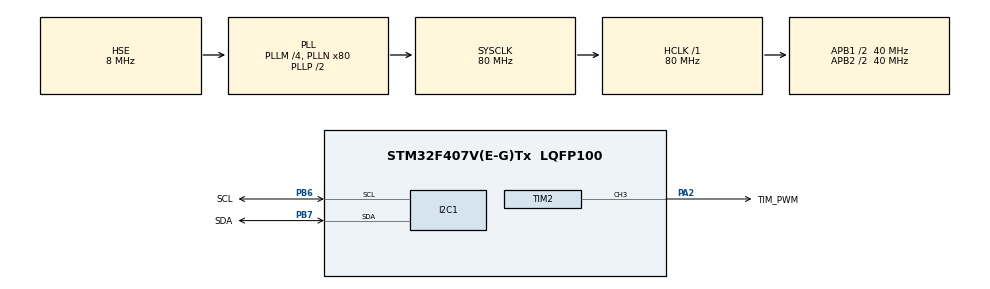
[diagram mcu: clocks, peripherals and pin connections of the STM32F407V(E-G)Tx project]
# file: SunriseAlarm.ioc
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I2C1.I2C_Mode=I2C_Fast
Mcu.Family=STM32F4
Mcu.Name=STM32F407V(E-G)Tx
Mcu.Package=LQFP100
NVIC.PriorityGroup=NVIC_PRIORITYGROUP_0
NVIC.TIM1_UP_TIM10_IRQn=true\:0\:0\:false\:false\:true\:true\:true\:true
PA2.GPIO_Label=TIM_PWM
PA2.Signal=S_TIM2_CH3
PB6.GPIO_Label=SCL
PB6.Mode=I2C
PB6.Signal=I2C1_SCL
PB7.GPIO_Label=SDA
PB7.Mode=I2C
PB7.Signal=I2C1_SDA
PC14-OSC32_IN.Mode=LSE-External-Oscillator
PC14-OSC32_IN.Signal=RCC_OSC32_IN
PC15-OSC32_OUT.Mode=LSE-External-Oscillator
PC15-OSC32_OUT.Signal=RCC_OSC32_OUT
PH0-OSC_IN.Mode=HSE-External-Oscillator
PH0-OSC_IN.Signal=RCC_OSC_IN
PH1-OSC_OUT.Mode=HSE-External-Oscillator
PH1-OSC_OUT.Signal=RCC_OSC_OUT
ProjectManager.HeapSize=0x200
ProjectManager.StackSize=0x400
ProjectManager.TargetToolchain=STM32CubeIDE
RCC.48MHZClocksFreq_Value=22857142.85714286
RCC.AHBFreq_Value=80000000
RCC.APB1CLKDivider=RCC_HCLK_DIV2
RCC.APB1Freq_Value=40000000
RCC.APB1TimFreq_Value=80000000
RCC.APB2CLKDivider=RCC_HCLK_DIV2
RCC.APB2Freq_Value=40000000
RCC.APB2TimFreq_Value=80000000
RCC.CortexFreq_Value=80000000
RCC.HCLKFreq_Value=80000000
RCC.HSE_VALUE=8000000
RCC.HSI_VALUE=16000000
RCC.PLLM=4
RCC.PLLN=80
RCC.PLLQ=7
RCC.PLLSourceVirtual=RCC_PLLSOURCE_HSE
RCC.SYSCLKFreq_VALUE=80000000
RCC.SYSCLKSource=RCC_SYSCLKSOURCE_PLLCLK
RCC.VCOOutputFreq_Value=160000000
SH.S_TIM2_CH3.0=TIM2_CH3,PWM Generation3 CH3
TIM10.Period=9999
TIM10.Prescaler=7999
TIM2.Channel-PWM\ Generation3\ CH3=TIM_CHANNEL_3
TIM2.Period=99
TIM2.Prescaler=7999
VP_TIM10_VS_ClockSourceINT.Mode=Enable_Timer
board=STM32F407G-DISC1

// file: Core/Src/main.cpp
/* USER CODE BEGIN Header */
/**
  ******************************************************************************
  * @file           : main.c
  * @brief          : Main program body
  ******************************************************************************
  * @attention
  *
  * Copyright (c) 2023 STMicroelectronics.
  * All rights reserved.
  *
  * This software is licensed under terms that can be found in the LICENSE file
  * in the root directory of this software component.
  * If no LICENSE file comes with this software, it is provided AS-IS.
  *
  ******************************************************************************
  */
/* USER CODE END Header */
#include "main.h"

/* USER CODE BEGIN Includes */
#include"ssd1306.h"
#include <string.h>
//#include "OLED_WindowAdapter.h"
/* USER CODE END Includes */

/* USER CODE BEGIN PD */
#define WRITE_COMMAND(cmd) Write_Command(0b01111000,cmd)
#define WRITE_DATA(dt) Write_Data(0b01111000,dt,sizeof(dt))
#define TURN_ON_DISP() WRITE_COMMAND(0x8D);WRITE_COMMAND(0x14);WRITE_COMMAND(0xAF)
/* USER CODE END PD */

I2C_HandleTypeDef hi2c1;

TIM_HandleTypeDef htim2;
TIM_HandleTypeDef htim10;

void SystemClock_Config(void);
static void MX_GPIO_Init(void);
static void MX_I2C1_Init(void);
static void MX_TIM2_Init(void);
static void MX_TIM10_Init(void);
/* USER CODE BEGIN PFP */
void DISP_INIT();
void Write_Data(uint16_t add,uint8_t* data,int buffSize);
void Write_Command(uint16_t add,uint8_t cmd);
/* USER CODE END PFP */

int main(void)
{
  /* USER CODE BEGIN 1 */
	//prSunrise::SSD1306_Adapter dispController(&hi2c1);
  /* USER CODE END 1 */

  /* MCU Configuration--------------------------------------------------------*/

  /* Reset of all peripherals, Initializes the Flash interface and the Systick. */
  HAL_Init();

  /* Configure the system clock */
  SystemClock_Config();

  /* Initialize all configured peripherals */
  MX_GPIO_Init();
  MX_I2C1_Init();
  MX_TIM2_Init();
  MX_TIM10_Init();
  /* USER CODE BEGIN 2 */
  DISP_INIT();
  int buffSize=128*8;
  uint8_t data[buffSize];
  for(int i=0;i<buffSize;++i){
		  data[i]=0x00;
  }

  data[0]=0x97;
  data[1]=0xAF;
  data[9]=0xFF;
  data[8*20+7]=0x13;
 // uint8_t dt[9];
  //dt[0]=0x40;
  //memcpy(dt+1,data,8);
  //HAL_I2C_Master_Transmit(&hi2c1, 0x78, dt, 8, 1000);
Write_Data(0b01111000, data, buffSize);
//SSD1306_Init();
//SSD1306_Fill(SSD1306_COLOR_BLACK);
//SSD1306_UpdateScreen();
  /* USER CODE END 2 */

  /* Infinite loop */
  while (1)
  {

    /* USER CODE BEGIN 3 */
	//SSD1306_GotoXY(0, 0);
	//SSD1306_Puts("12:40", &Font_16x26, SSD1306_COLOR_WHITE);
	//SSD1306_UpdateScreen();
  }
  /* USER CODE END 3 */
}

void SystemClock_Config(void)
{
  RCC_OscInitTypeDef RCC_OscInitStruct = {0};
  RCC_ClkInitTypeDef RCC_ClkInitStruct = {0};

  /** Configure the main internal regulator output voltage
  */
  __HAL_RCC_PWR_CLK_ENABLE();
  __HAL_PWR_VOLTAGESCALING_CONFIG(PWR_REGULATOR_VOLTAGE_SCALE1);

  /** Initializes the RCC Oscillators according to the specified parameters
  * in the RCC_OscInitTypeDef structure.
  */
  RCC_OscInitStruct.OscillatorType = RCC_OSCILLATORTYPE_HSE;
  RCC_OscInitStruct.HSEState = RCC_HSE_ON;
  RCC_OscInitStruct.PLL.PLLState = RCC_PLL_ON;
  RCC_OscInitStruct.PLL.PLLSource = RCC_PLLSOURCE_HSE;
  RCC_OscInitStruct.PLL.PLLM = 4;
  RCC_OscInitStruct.PLL.PLLN = 80;
  RCC_OscInitStruct.PLL.PLLP = RCC_PLLP_DIV2;
  RCC_OscInitStruct.PLL.PLLQ = 7;
  if (HAL_RCC_OscConfig(&RCC_OscInitStruct) != HAL_OK)
  {
    Error_Handler();
  }

  /** Initializes the CPU, AHB and APB buses clocks
  */
  RCC_ClkInitStruct.ClockType = RCC_CLOCKTYPE_HCLK|RCC_CLOCKTYPE_SYSCLK
                              |RCC_CLOCKTYPE_PCLK1|RCC_CLOCKTYPE_PCLK2;
  RCC_ClkInitStruct.SYSCLKSource = RCC_SYSCLKSOURCE_PLLCLK;
  RCC_ClkInitStruct.AHBCLKDivider = RCC_SYSCLK_DIV1;
  RCC_ClkInitStruct.APB1CLKDivider = RCC_HCLK_DIV2;
  RCC_ClkInitStruct.APB2CLKDivider = RCC_HCLK_DIV2;

  if (HAL_RCC_ClockConfig(&RCC_ClkInitStruct, FLASH_LATENCY_2) != HAL_OK)
  {
    Error_Handler();
  }
}

static void MX_I2C1_Init(void)
{

  hi2c1.Instance = I2C1;
  hi2c1.Init.ClockSpeed = 400000;
  hi2c1.Init.DutyCycle = I2C_DUTYCYCLE_2;
  hi2c1.Init.OwnAddress1 = 0;
  hi2c1.Init.AddressingMode = I2C_ADDRESSINGMODE_7BIT;
  hi2c1.Init.DualAddressMode = I2C_DUALADDRESS_DISABLE;
  hi2c1.Init.OwnAddress2 = 0;
  hi2c1.Init.GeneralCallMode = I2C_GENERALCALL_DISABLE;
  hi2c1.Init.NoStretchMode = I2C_NOSTRETCH_DISABLE;
  if (HAL_I2C_Init(&hi2c1) != HAL_OK)
  {
    Error_Handler();
  }

}

static void MX_TIM2_Init(void)
{

  TIM_MasterConfigTypeDef sMasterConfig = {0};
  TIM_OC_InitTypeDef sConfigOC = {0};

  htim2.Instance = TIM2;
  htim2.Init.Prescaler = 7999;
  htim2.Init.CounterMode = TIM_COUNTERMODE_UP;
  htim2.Init.Period = 99;
  htim2.Init.ClockDivision = TIM_CLOCKDIVISION_DIV1;
  htim2.Init.AutoReloadPreload = TIM_AUTORELOAD_PRELOAD_DISABLE;
  if (HAL_TIM_PWM_Init(&htim2) != HAL_OK)
  {
    Error_Handler();
  }
  sMasterConfig.MasterOutputTrigger = TIM_TRGO_RESET;
  sMasterConfig.MasterSlaveMode = TIM_MASTERSLAVEMODE_DISABLE;
  if (HAL_TIMEx_MasterConfigSynchronization(&htim2, &sMasterConfig) != HAL_OK)
  {
    Error_Handler();
  }
  sConfigOC.OCMode = TIM_OCMODE_PWM1;
  sConfigOC.Pulse = 0;
  sConfigOC.OCPolarity = TIM_OCPOLARITY_HIGH;
  sConfigOC.OCFastMode = TIM_OCFAST_DISABLE;
  if (HAL_TIM_PWM_ConfigChannel(&htim2, &sConfigOC, TIM_CHANNEL_3) != HAL_OK)
  {
    Error_Handler();
  }
  HAL_TIM_MspPostInit(&htim2);

}

static void MX_TIM10_Init(void)
{

  htim10.Instance = TIM10;
  htim10.Init.Prescaler = 7999;
  htim10.Init.CounterMode = TIM_COUNTERMODE_UP;
  htim10.Init.Period = 9999;
  htim10.Init.ClockDivision = TIM_CLOCKDIVISION_DIV1;
  htim10.Init.AutoReloadPreload = TIM_AUTORELOAD_PRELOAD_DISABLE;
  if (HAL_TIM_Base_Init(&htim10) != HAL_OK)
  {
    Error_Handler();
  }

}

static void MX_GPIO_Init(void)
{

  /* GPIO Ports Clock Enable */
  __HAL_RCC_GPIOC_CLK_ENABLE();
  __HAL_RCC_GPIOH_CLK_ENABLE();
  __HAL_RCC_GPIOA_CLK_ENABLE();
  __HAL_RCC_GPIOB_CLK_ENABLE();

}

/* USER CODE BEGIN 4 */

void Write_Command(uint16_t add,uint8_t cmd){
	uint8_t dataBuff[2];
	dataBuff[0]=0x00;
	dataBuff[1]=cmd;
	HAL_I2C_Master_Transmit(&hi2c1,add, dataBuff, 2, 10);
}
void Write_Data(uint16_t add,uint8_t* data,int buffSize){
	uint8_t dt[buffSize+1];
	dt[0]=0x40;
	memcpy(dt+1,data,buffSize);
	HAL_I2C_Master_Transmit(&hi2c1, add, dt, buffSize, 100);

}
void DISP_INIT(){
	WRITE_COMMAND(0xAE);
	{// ADDRESSING MODE
	WRITE_COMMAND(0x20);
		WRITE_COMMAND(0x01);// vertical addressing mode, 00 for horizontal and 10 for page one.
	WRITE_COMMAND(0x21);//Set up the column addresses
		WRITE_COMMAND(0x00);//first column
		WRITE_COMMAND(0x7F);//last column
	WRITE_COMMAND(0x22);// Set up pages addresses
		WRITE_COMMAND(0x00);//first
		WRITE_COMMAND(0x7);//last
	}
	{// SET MULTIPLEXER SIZE (SPACE OF THE BUFFER AVAILABLE)
		WRITE_COMMAND(0xA8);
		WRITE_COMMAND(0x3F);
	}
	{// SET DISPLAY OFFSET
		WRITE_COMMAND(0xD3);
		WRITE_COMMAND(0x00);//0 offset
	}
	{ // SET START LINE
		WRITE_COMMAND(0x40);//0x40
	}
	{//SET SEGMENT REMAP (COLUMNS) AND SET COM OUTPUT SCAN DIRECTION
		WRITE_COMMAND(0xA1);//COLUMNS REMAP
		WRITE_COMMAND(0xC8);//UP DOWN
	}
	{//SET COM PINS CONFIG
		WRITE_COMMAND(0xDA);
		WRITE_COMMAND(0x12);//(RESET)
	}
	{
	//Set Contrast
		WRITE_COMMAND(0x81);
		WRITE_COMMAND(0x7F);//CONTRAST LEVEL
	}
	{//ON DISP-RAM AND NORMAL MODE
		WRITE_COMMAND(0xA4);
		WRITE_COMMAND(0xA6);// Set normal mode for RAM
	}
	{
		//SET UP CLOCK
		WRITE_COMMAND(0xD5);
		WRITE_COMMAND(0x80);
	}
	{// PRE-CHARGE PERIOD
		WRITE_COMMAND(0xD9);
		WRITE_COMMAND(0x22);
	}
	{//SET COMMON HIGH VOLTAGE DESELECT LEVEL
		WRITE_COMMAND(0xDB);
		WRITE_COMMAND(0x20);
	}
	TURN_ON_DISP();
}

/* USER CODE END 4 */

void Error_Handler(void)
{
  __disable_irq();
  while (1)
  {
  }
}
